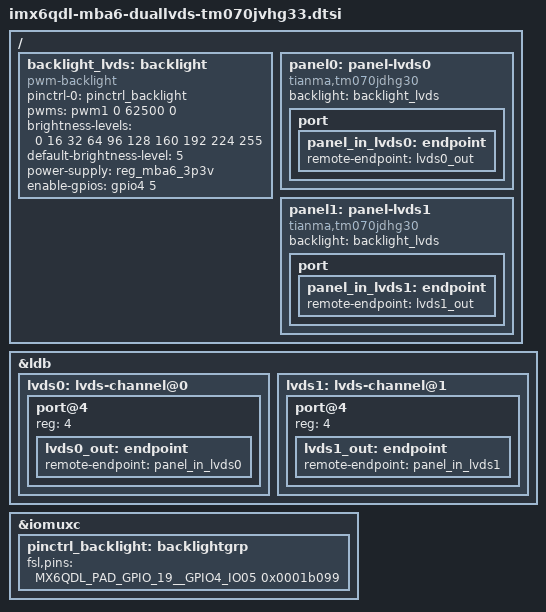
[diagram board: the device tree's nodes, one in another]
// SPDX-License-Identifier: GPL-2.0-only
/*
 * Copyright 2019-2022 TQ-Systems GmbH
 * Author: Markus Niebel <Markus.Niebel@tq-group.com>
 * Author: Alexander Stein <Alexander.Stein@tq-group.com>
 */

/ {
	backlight_lvds: backlight {
		compatible = "pwm-backlight";
		pinctrl-names = "default";
		pinctrl-0 = <&pinctrl_backlight>;
		pwms = <&pwm1 0 62500 0>;
		brightness-levels = <0 16 32 64 96 128 160 192 224 255>;
		default-brightness-level = <5>;
		power-supply = <&reg_mba6_3p3v>;
		enable-gpios = <&gpio4 5 GPIO_ACTIVE_HIGH>;
		status = "okay";
	};

	panel0: panel-lvds0 {
		compatible = "tianma,tm070jdhg30";
		backlight = <&backlight_lvds>;

		port {
			panel_in_lvds0: endpoint {
				remote-endpoint = <&lvds0_out>;
			};
		};
	};

	panel1: panel-lvds1 {
		compatible = "tianma,tm070jdhg30";
		backlight = <&backlight_lvds>;

		port {
			panel_in_lvds1: endpoint {
				remote-endpoint = <&lvds1_out>;
			};
		};
	};
};

&ldb {
	status = "okay";

	lvds0: lvds-channel@0 {
		status = "okay";

		port@4 {
			reg = <4>;

			lvds0_out: endpoint {
				remote-endpoint = <&panel_in_lvds0>;
			};
		};
	};

	lvds1: lvds-channel@1 {
		status = "okay";

		port@4 {
			reg = <4>;

			lvds1_out: endpoint {
				remote-endpoint = <&panel_in_lvds1>;
			};
		};
	};
};

&iomuxc {
	pinctrl_backlight: backlightgrp {
		fsl,pins = <
			/* LCD.BLT_EN */
			MX6QDL_PAD_GPIO_19__GPIO4_IO05 0x0001b099
		>;
	};
};
